# PIC32CM6408PL10032 device description
Architecture: CORTEX-M0PLUS; Family: PIC32CMPL; Series: PIC32CMPL10
Registers are 32-bit, read-write, reset 0x0 unless marked. A register's access mark holds for its fields unless they carry their own. Offsets are from the block's base; [hi:lo] are bit positions; 'fields as' and 'values as' point back to an identical list.

## SystemControl — System Control Registers
Instances: SystemControl 0xE000E000
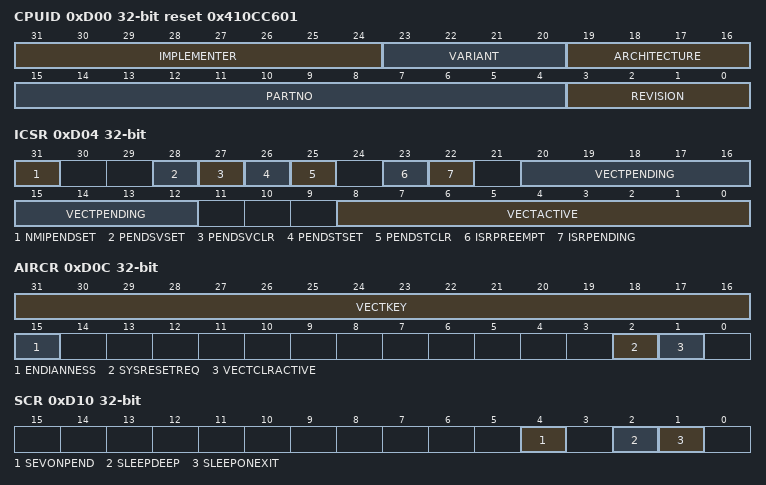
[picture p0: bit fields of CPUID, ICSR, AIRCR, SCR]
0xD00 CPUID ro reset 0x410CC601 — CPUID Base Register
  [31:24] IMPLEMENTER — Implementer code, ARM=0x41
  [23:20] VARIANT — Major revision number
  [19:16] ARCHITECTURE — Processor Architecture, 0xC=ARMv6-M
  [15:4] PARTNO — Processor Part Number, 0xC60=Cortex-M0+
  [3:0] REVISION — Minor revision number
0xD04 ICSR — Interrupt Control and State Register
  [31] NMIPENDSET — NMI set-pending bit
    0=Write: no effect; read: NMI exception is not pending; 1=Write: changes NMI exception state to pending; read: NMI exception is pending
  [28] PENDSVSET — PendSV set-pending bit
    0=Write: no effect; read: PendSV exception is not pending; 1=Write: changes PendSV exception state to pending; read: PendSV exception is pending
  [27] PENDSVCLR — PendSV clear-pending bit
    0=No effect; 1=Removes the pending state from the PendSV exception
  [26] PENDSTSET — SysTick exception set-pending bit
    0=Write: no effect; read: SysTick exception is not pending; 1=Write: changes SysTick exception state to pending; read: SysTick exception is pending
  [25] PENDSTCLR — SysTick exception clear-pending bit
    0=No effect; 1=Removes the pending state from the SysTick exception
  [23] ISRPREEMPT — Debug: Pending exception serviced on exit from debug halt
  [22] ISRPENDING — Debug: NVIC interrupt pending
  [20:12] VECTPENDING — Exception number of the highest priority pending enabled exception
  [8:0] VECTACTIVE — Debug: Exception number of currently executing exception, or 0 if thread mode
0xD08 VTOR — Vector Table Offset Register
  [31:7] TBLOFF — Vector table base offset
0xD0C AIRCR — Application Interrupt and Reset Control Register
  [31:16] VECTKEY — Register key (0x05FA)
  [15] ENDIANNESS — Data Endianness, 0=little, 1=big
    0=Little-endian; 1=Big-endian
  [2] SYSRESETREQ — System Reset Request
    0=No system reset request; 1=Asserts a signal to the outer system that requests a reset
  [1] VECTCLRACTIVE — Debug: Clear state information
0xD10 SCR — System Control Register
  [4] SEVONPEND — Send Event on Pending bit
    0=Only enabled interrupts or events can wakeup the processor, disabled interrupts are excluded; 1=Enabled events and all interrupts, including disabled interrupts, can wakeup the processor
  [2] SLEEPDEEP — Uses Deep Sleep as low power mode
    0=Sleep; 1=Deep sleep
  [1] SLEEPONEXIT — Sleep-On-Exit when exiting Handler mode
    0=O not sleep when returning to Thread mode; 1=Enter sleep, or deep sleep, on return from an ISR
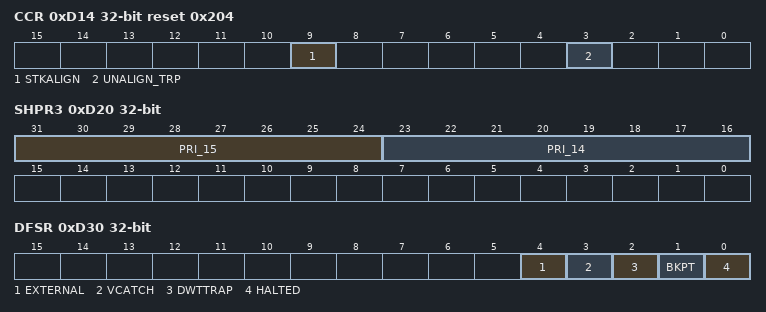
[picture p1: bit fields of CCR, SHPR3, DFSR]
0xD14 CCR ro reset 0x204 — Configuration and Control Register
  [9] STKALIGN — Stack 8-byte aligned on exception entry
    0=4-byte aligned; 1=8-byte aligned
  [3] UNALIGN_TRP — Unaligned accesses generates a Hard Fault
    0=Do not trap unaligned halfword and word accesses; 1=Trap unaligned halfword and word accesses
0xD1C SHPR2 — System Handler Priority Register 2
  [31:24] PRI_11 — Priority of system handler 11, SVCall
0xD20 SHPR3 — System Handler Priority Register 3
  [31:24] PRI_15 — Priority of system handler 15, SysTick exception
  [23:16] PRI_14 — Priority of system handler 14, PendSV
0xD24 SHCSR — System Handler Control and State Register
  [15] SVCALLPENDED
0xD30 DFSR — Debug Fault Status Register
  [4] EXTERNAL — EDBGRQ debug event
  [3] VCATCH — Vector catch debug event
  [2] DWTTRAP — DWT debug event
  [1] BKPT — Breakpoint debug event
  [0] HALTED — Halt request debug event active

## WDT — Watchdog Timer
Instances: WDT 0x40002000
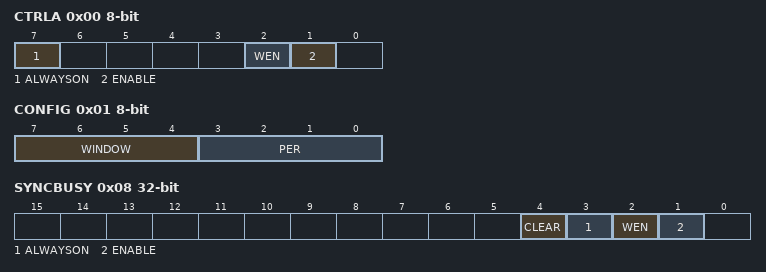
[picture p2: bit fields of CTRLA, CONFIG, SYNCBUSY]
0x00 CTRLA 8-bit reset not defined (WSYNC) — Control A
  [7] ALWAYSON
  [2] WEN — Watchdog Timer Window Mode Enable
  [1] ENABLE
0x01 CONFIG 8-bit reset not defined — Configuration
  [7:4] WINDOW — Window Mode Time-Out Period
    0=CYC8 (8 clock cycles); 1=CYC16 (16 clock cycles); 2=CYC32 (32 clock cycles); 3=CYC64 (64 clock cycles); 4=CYC128 (128 clock cycles); 5=CYC256 (256 clock cycles); 6=CYC512 (512 clock cycles); 7=CYC1024 (1024 clock cycles); 8=CYC2048 (2048 clock cycles); 9=CYC4096 (4096 clock cycles); 10=CYC8192 (8192 clock cycles); 11=CYC16384 (16384 clock cycles)
  [3:0] PER — Time-Out Period
    values as WINDOW
0x02 EWCTRL 8-bit reset not defined — Early Warning Control
  [3:0] EWOFFSET — Early Warning Interrupt Time Offset
    values as CONFIG.WINDOW
0x04 INTENCLR 8-bit (atomic clear) — Interrupt Enable Clear
  [0] EW — Early Warning Interrupt Enable
0x05 INTENSET 8-bit (atomic set) — Interrupt Enable Set
  [0] EW — Early Warning Interrupt Enable
0x06 INTFLAG 8-bit (atomic clear) — Interrupt Flag Status and Clear
  [0] EW — Early Warning
0x08 SYNCBUSY ro — Synchronization Busy
  [4] CLEAR — CLEAR Synchronization Busy
  [3] ALWAYSON — ALWAYSON Synchronization Busy
  [2] WEN — Window Enable Synchronization Busy
  [1] ENABLE — Enable Synchronization Busy
0x0C CLEAR 8-bit wo (WSYNC)
  [7:0] CLEAR — Watchdog Clear
    165=KEY (In Normal mode, writing during the WDT time-out period will clear the WDT and restart the WDT time-out period.(1) In Window mode, writing during the open window will clear the WDT and restart the WDT time-out sequence.(2))

## Notices in the file
Copyright (c) 2025 Microchip Technology Inc.
SPDX-License-Identifier: Apache-2.0
Licensed under the Apache License, Version 2.0 (the "License");
you may not use this file except in compliance with the License.
You may obtain a copy of the License at
http://www.apache.org/licenses/LICENSE-2.0
Unless required by applicable law or agreed to in writing, software
distributed under the License is distributed on an "AS IS" BASIS,
WITHOUT WARRANTIES OR CONDITIONS OF ANY KIND, either express or implied.
See the License for the specific language governing permissions and
limitations under the License.
